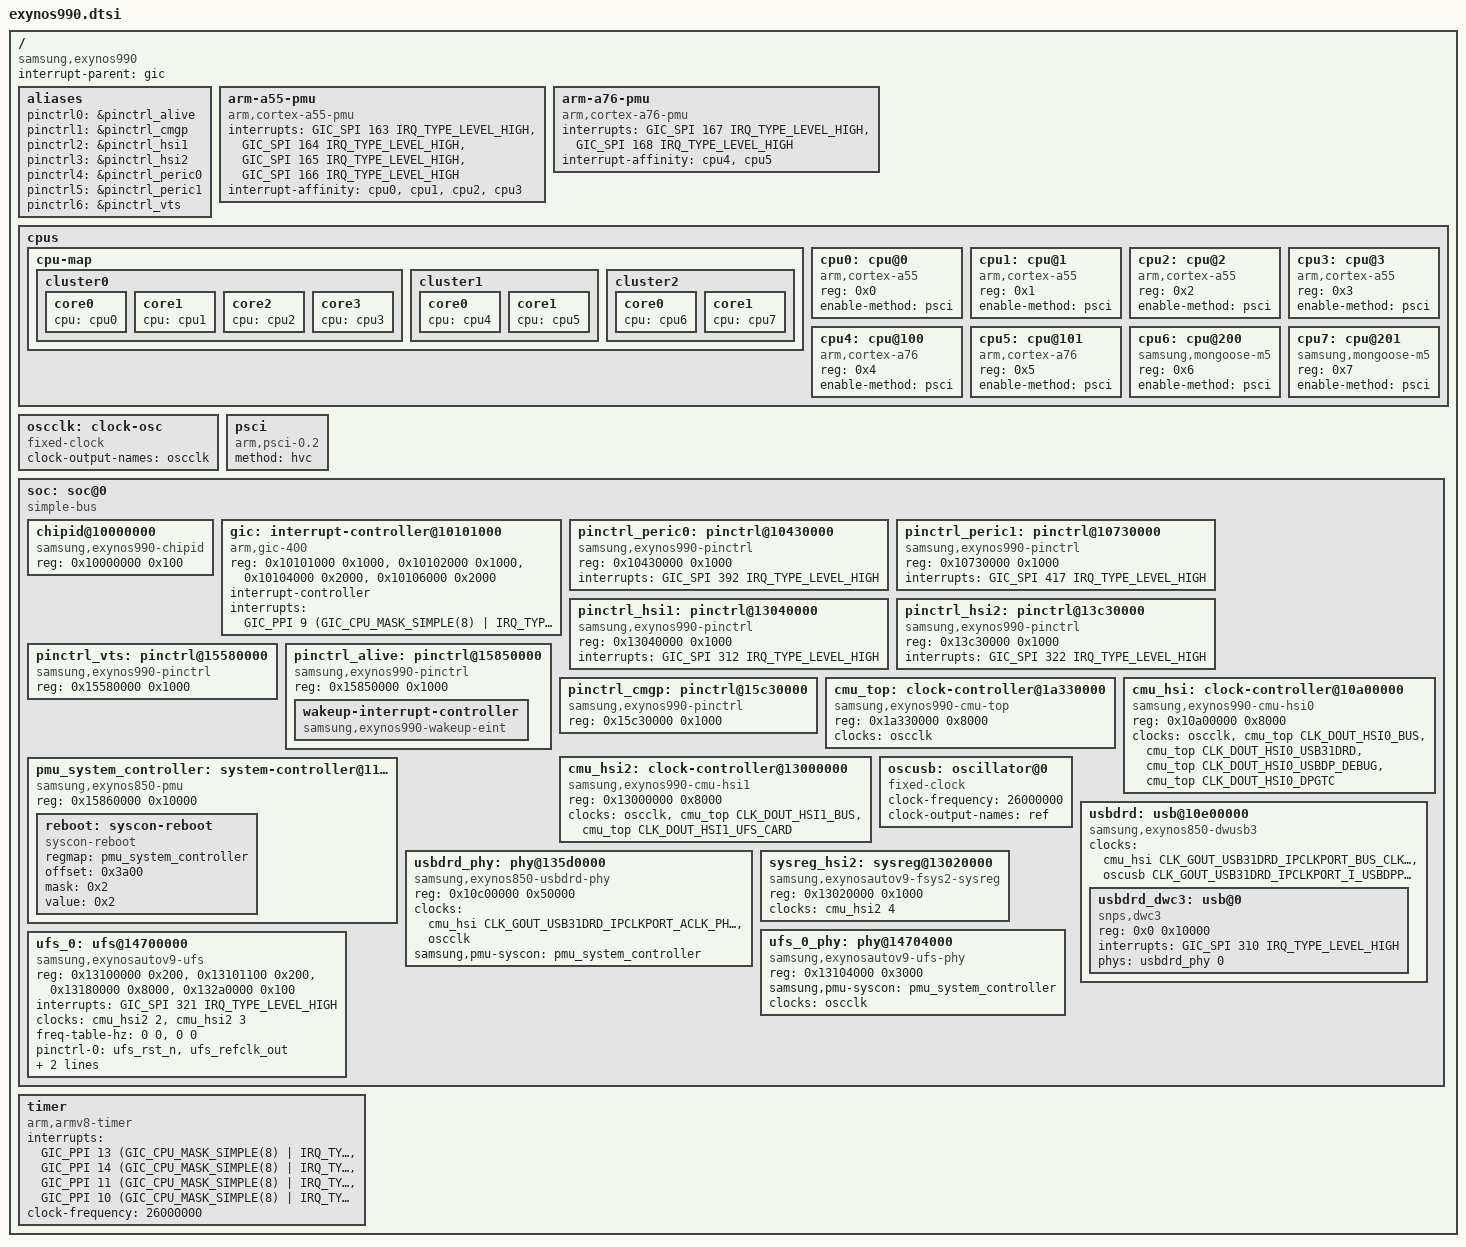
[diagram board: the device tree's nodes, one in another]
// SPDX-License-Identifier: GPL-2.0 OR BSD-3-Clause
/*
 * Samsung Exynos 990 SoC device tree source
 *
 * Copyright (c) 2024, Igor Belwon <igor.belwon@mentallysanemainliners.org>
 */

#include <dt-bindings/interrupt-controller/arm-gic.h>
#include <dt-bindings/clock/exynos990.h>

/ {
	compatible = "samsung,exynos990";
	#address-cells = <2>;
	#size-cells = <1>;

	interrupt-parent = <&gic>;

	aliases {
		pinctrl0 = &pinctrl_alive;
		pinctrl1 = &pinctrl_cmgp;
		pinctrl2 = &pinctrl_hsi1;
		pinctrl3 = &pinctrl_hsi2;
		pinctrl4 = &pinctrl_peric0;
		pinctrl5 = &pinctrl_peric1;
		pinctrl6 = &pinctrl_vts;
	};

	arm-a55-pmu {
		compatible = "arm,cortex-a55-pmu";
		interrupts = <GIC_SPI 163 IRQ_TYPE_LEVEL_HIGH>,
			     <GIC_SPI 164 IRQ_TYPE_LEVEL_HIGH>,
			     <GIC_SPI 165 IRQ_TYPE_LEVEL_HIGH>,
			     <GIC_SPI 166 IRQ_TYPE_LEVEL_HIGH>;

		interrupt-affinity = <&cpu0>,
				     <&cpu1>,
				     <&cpu2>,
				     <&cpu3>;
	};

	arm-a76-pmu {
		compatible = "arm,cortex-a76-pmu";
		interrupts = <GIC_SPI 167 IRQ_TYPE_LEVEL_HIGH>,
			     <GIC_SPI 168 IRQ_TYPE_LEVEL_HIGH>;

		interrupt-affinity = <&cpu4>,
				     <&cpu5>;
	};

	/* There's no PMU model for cluster2, which are the Mongoose cores. */

	cpus {
		#address-cells = <1>;
		#size-cells = <0>;

		cpu-map {
			cluster0 {
				core0 {
					cpu = <&cpu0>;
				};

				core1 {
					cpu = <&cpu1>;
				};

				core2 {
					cpu = <&cpu2>;
				};

				core3 {
					cpu = <&cpu3>;
				};
			};

			cluster1 {
				core0 {
					cpu = <&cpu4>;
				};

				core1 {
					cpu = <&cpu5>;
				};
			};

			cluster2 {
				core0 {
					cpu = <&cpu6>;
				};

				core1 {
					cpu = <&cpu7>;
				};
			};
		};

		cpu0: cpu@0 {
			device_type = "cpu";
			compatible = "arm,cortex-a55";
			reg = <0x0>;
			enable-method = "psci";
		};

		cpu1: cpu@1 {
			device_type = "cpu";
			compatible = "arm,cortex-a55";
			reg = <0x1>;
			enable-method = "psci";
		};

		cpu2: cpu@2 {
			device_type = "cpu";
			compatible = "arm,cortex-a55";
			reg = <0x2>;
			enable-method = "psci";
		};

		cpu3: cpu@3 {
			device_type = "cpu";
			compatible = "arm,cortex-a55";
			reg = <0x3>;
			enable-method = "psci";
		};

		cpu4: cpu@100 {
			device_type = "cpu";
			compatible = "arm,cortex-a76";
			reg = <0x4>;
			enable-method = "psci";
		};

		cpu5: cpu@101 {
			device_type = "cpu";
			compatible = "arm,cortex-a76";
			reg = <0x5>;
			enable-method = "psci";
		};

		cpu6: cpu@200 {
			device_type = "cpu";
			compatible = "samsung,mongoose-m5";
			reg = <0x6>;
			enable-method = "psci";
		};

		cpu7: cpu@201 {
			device_type = "cpu";
			compatible = "samsung,mongoose-m5";
			reg = <0x7>;
			enable-method = "psci";
		};
	};

	oscclk: clock-osc {
		compatible = "fixed-clock";
		#clock-cells = <0>;
		clock-output-names = "oscclk";
	};

	psci {
		compatible = "arm,psci-0.2";
		method = "hvc";
	};

	soc: soc@0 {
		compatible = "simple-bus";
		ranges = <0x0 0x0 0x0 0x20000000>;

		#address-cells = <1>;
		#size-cells = <1>;

		chipid@10000000 {
			compatible = "samsung,exynos990-chipid",
				     "samsung,exynos850-chipid";
			reg = <0x10000000 0x100>;
		};

		gic: interrupt-controller@10101000 {
			compatible = "arm,gic-400";
			reg = <0x10101000 0x1000>,
			      <0x10102000 0x1000>,
			      <0x10104000 0x2000>,
			      <0x10106000 0x2000>;
			#interrupt-cells = <3>;
			interrupt-controller;
			interrupts = <GIC_PPI 9 (GIC_CPU_MASK_SIMPLE(8) |
						 IRQ_TYPE_LEVEL_HIGH)>;
			#address-cells = <0>;
			#size-cells = <1>;
		};

		pinctrl_peric0: pinctrl@10430000 {
			compatible = "samsung,exynos990-pinctrl";
			reg = <0x10430000 0x1000>;
			interrupts = <GIC_SPI 392 IRQ_TYPE_LEVEL_HIGH>;
		};

		pinctrl_peric1: pinctrl@10730000 {
			compatible = "samsung,exynos990-pinctrl";
			reg = <0x10730000 0x1000>;
			interrupts = <GIC_SPI 417 IRQ_TYPE_LEVEL_HIGH>;
		};

		pinctrl_hsi1: pinctrl@13040000 {
			compatible = "samsung,exynos990-pinctrl";
			reg = <0x13040000 0x1000>;
			interrupts = <GIC_SPI 312 IRQ_TYPE_LEVEL_HIGH>;
		};

		pinctrl_hsi2: pinctrl@13c30000 {
			compatible = "samsung,exynos990-pinctrl";
			reg = <0x13c30000 0x1000>;
			interrupts = <GIC_SPI 322 IRQ_TYPE_LEVEL_HIGH>;
		};

		pinctrl_vts: pinctrl@15580000 {
			compatible = "samsung,exynos990-pinctrl";
			reg = <0x15580000 0x1000>;
		};

		pinctrl_alive: pinctrl@15850000 {
			compatible = "samsung,exynos990-pinctrl";
			reg = <0x15850000 0x1000>;

			wakeup-interrupt-controller {
				compatible = "samsung,exynos990-wakeup-eint",
					     "samsung,exynos850-wakeup-eint",
					     "samsung,exynos7-wakeup-eint";
			};
		};

		pinctrl_cmgp: pinctrl@15c30000 {
			compatible = "samsung,exynos990-pinctrl";
			reg = <0x15c30000 0x1000>;
		};

		/* WORKING TREE - 31 Oct. 2024 - ibelwon */

		/* clk */
		cmu_top: clock-controller@1a330000 {
			compatible = "samsung,exynos990-cmu-top";
			reg = <0x1a330000 0x8000>;
			#clock-cells = <1>;

			clocks = <&oscclk>;
			clock-names = "oscclk";
		};

		cmu_hsi: clock-controller@10a00000 {
			compatible = "samsung,exynos990-cmu-hsi0";
			reg = <0x10a00000 0x8000>;
			#clock-cells = <1>;

			clocks = <&oscclk>, <&cmu_top CLK_DOUT_HSI0_BUS>,
					 <&cmu_top CLK_DOUT_HSI0_USB31DRD>,
					 <&cmu_top CLK_DOUT_HSI0_USBDP_DEBUG>,
					 <&cmu_top CLK_DOUT_HSI0_DPGTC>;
			clock-names = "oscclk", "dout_hsi0_bus",
						  "dout_hsi0_usb31drd",
						  "dout_hsi0_usbdp_debug",
						  "dout_hsi0_dpgtc";
		};

		cmu_hsi2: clock-controller@13000000 {
			compatible = "samsung,exynos990-cmu-hsi1";
			reg = <0x13000000 0x8000>;
			#clock-cells = <1>;

			clocks = <&oscclk>, <&cmu_top CLK_DOUT_HSI1_BUS>,
					 <&cmu_top CLK_DOUT_HSI1_UFS_CARD>;
			clock-names = "oscclk", "dout_hsi1_bus",
						  "dout_hsi1_ufs_embd";
		};

		/* usb sysreg (hsi0) */
		pmu_system_controller: system-controller@11860000 {
			compatible = "samsung,exynos850-pmu", "syscon";
			reg = <0x15860000 0x10000>;

			reboot: syscon-reboot {
				compatible = "syscon-reboot";
				regmap = <&pmu_system_controller>;
				offset = <0x3a00>; /* SYSTEM_CONFIGURATION */
				mask = <0x2>; /* SWRESET_SYSTEM */
				value = <0x2>; /* reset value */
			};
		};

		/* NO. */
		oscusb: oscillator@0 {
        	compatible = "fixed-clock";
        	#clock-cells = <1>;
        	clock-frequency  = <26000000>;
        	clock-output-names = "ref";
    	};

		/* usb PAIN */
		usbdrd: usb@10e00000 {
			compatible = "samsung,exynos850-dwusb3";
			ranges = <0x0 0x10e00000 0x10000>;
			clocks = <&cmu_hsi CLK_GOUT_USB31DRD_IPCLKPORT_BUS_CLK_EARLY>,
				 <&oscusb CLK_GOUT_USB31DRD_IPCLKPORT_I_USBDPPHY_REF_SOC_PLL>;
			clock-names = "bus_early", "ref";
			#address-cells = <1>;
			#size-cells = <1>;
			status = "okay";

			usbdrd_dwc3: usb@0 {
				compatible = "snps,dwc3";
				reg = <0x0 0x10000>;
				interrupts = <GIC_SPI 310 IRQ_TYPE_LEVEL_HIGH>;
				phys = <&usbdrd_phy 0>;
				phy-names = "usb2-phy";
			};
		};

		usbdrd_phy: phy@135d0000 {
			compatible = "samsung,exynos850-usbdrd-phy";
			reg = <0x10c00000 0x50000>;
			clocks = <&cmu_hsi CLK_GOUT_USB31DRD_IPCLKPORT_ACLK_PHYCTRL>,
				 <&oscclk>;
			clock-names = "phy", "ref";
			samsung,pmu-syscon = <&pmu_system_controller>;
			#phy-cells = <1>;
			status = "okay";
		};

		sysreg_hsi2: sysreg@13020000 {
			compatible = "samsung,exynosautov9-fsys2-sysreg",
				     "samsung,exynosautov9-sysreg", "syscon";
			reg = <0x13020000 0x1000>;
			clocks = <&cmu_hsi2 4>;
		};

		ufs_0: ufs@14700000 {
			compatible = "samsung,exynosautov9-ufs";
			reg = <0x13100000 0x200>,
			      <0x13101100 0x200>,
			      <0x13180000 0x8000>,
			      <0x132a0000 0x100>;
			reg-names = "hci", "vs_hci", "unipro", "ufsp";
			interrupts = <GIC_SPI 321 IRQ_TYPE_LEVEL_HIGH>;
			clocks = <&cmu_hsi2 2>,
				 <&cmu_hsi2 3>;
			clock-names = "core_clk", "sclk_unipro_main";
			freq-table-hz = <0 0>, <0 0>;
			pinctrl-0 = <&ufs_rst_n &ufs_refclk_out>;
			pinctrl-names = "default";
			phys = <&ufs_0_phy>;
			phy-names = "ufs-phy";
			samsung,sysreg = <&sysreg_hsi2 0x700>;
			status = "okay";
		};

		ufs_0_phy: phy@14704000 {
			compatible = "samsung,exynosautov9-ufs-phy";
			reg = <0x13104000 0x3000>;
			reg-names = "phy-pma";
			samsung,pmu-syscon = <&pmu_system_controller>;
			#phy-cells = <0>;
			clocks = <&oscclk>;
			clock-names = "ref_clk";
			status = "okay";
		};
	};

	timer {
		compatible = "arm,armv8-timer";
		interrupts = <GIC_PPI 13 (GIC_CPU_MASK_SIMPLE(8) | IRQ_TYPE_LEVEL_LOW)>,
			     <GIC_PPI 14 (GIC_CPU_MASK_SIMPLE(8) | IRQ_TYPE_LEVEL_LOW)>,
			     <GIC_PPI 11 (GIC_CPU_MASK_SIMPLE(8) | IRQ_TYPE_LEVEL_LOW)>,
			     <GIC_PPI 10 (GIC_CPU_MASK_SIMPLE(8) | IRQ_TYPE_LEVEL_LOW)>;

		/*
		 * Non-updatable, broken stock Samsung bootloader does not
		 * configure CNTFRQ_EL0
		 */
		clock-frequency = <26000000>;
	};
};

#include "exynos990-pinctrl.dtsi"
